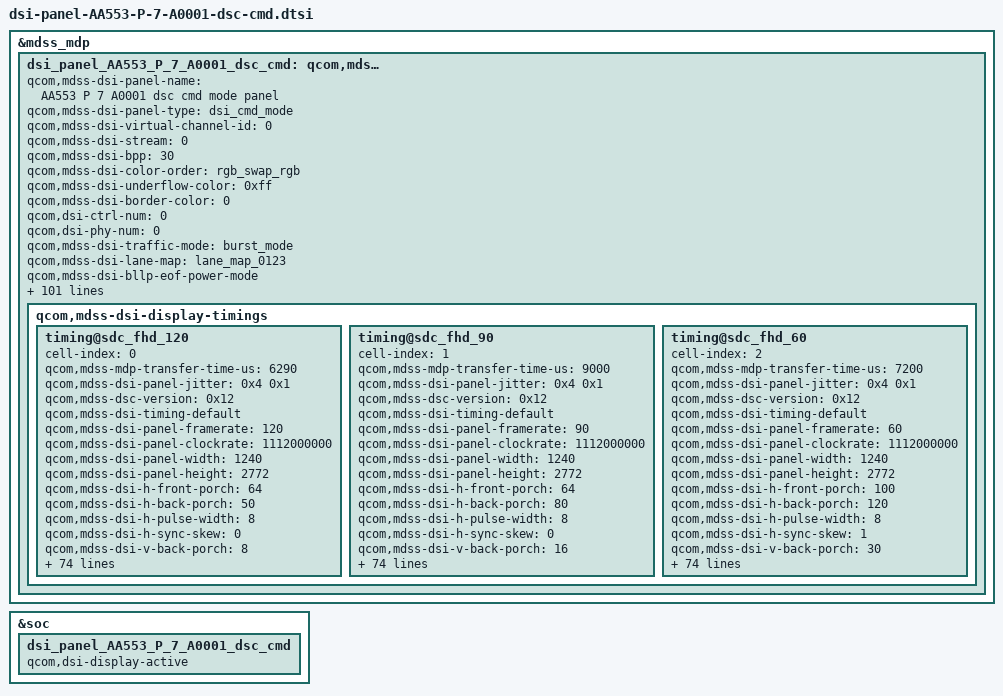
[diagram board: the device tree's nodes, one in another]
&mdss_mdp {
	dsi_panel_AA553_P_7_A0001_dsc_cmd: qcom,mdss_dsi_panel_AA553_P_7_A0001_dsc_cmd {
		qcom,mdss-dsi-panel-name = "AA553 P 7 A0001 dsc cmd mode panel";
		qcom,mdss-dsi-panel-type = "dsi_cmd_mode";
		qcom,mdss-dsi-virtual-channel-id = <0>;
		qcom,mdss-dsi-stream = <0>;
		qcom,mdss-dsi-bpp = <30>;
		qcom,mdss-dsi-color-order = "rgb_swap_rgb";
		qcom,mdss-dsi-underflow-color = <0xff>;
		qcom,mdss-dsi-border-color = <0>;
		qcom,dsi-ctrl-num = <0>;
		qcom,dsi-phy-num = <0>;
		qcom,mdss-dsi-traffic-mode = "burst_mode";
		qcom,mdss-dsi-lane-map = "lane_map_0123";
		qcom,mdss-dsi-bllp-eof-power-mode;
		qcom,mdss-dsi-bllp-power-mode;
		qcom,mdss-dsi-lane-0-state;
		qcom,mdss-dsi-lane-1-state;
		qcom,mdss-dsi-lane-2-state;
		qcom,mdss-dsi-lane-3-state;
		qcom,mdss-dsi-dma-trigger = "trigger_sw";
		qcom,mdss-dsi-dma-schedule-line = <1>;
		qcom,mdss-dsi-dma-schedule-window = <10>;
		qcom,mdss-dsi-mdp-trigger = "none";
		qcom,mdss-dsi-reset-sequence = <1 2>, <0 5>, <1 25>;
		qcom,mdss-dsi-te-pin-select = <1>;
		qcom,mdss-dsi-te-dcs-command = <1>;
		qcom,mdss-pan-physical-width-dimension = <70>;
		qcom,mdss-pan-physical-height-dimension = <156>;
		qcom,mdss-dsi-init-delay-us = <1000>;
		qcom,mdss-dsi-te-check-enable;
		qcom,mdss-dsi-te-using-te-pin;
		//qcom,mdss-dsi-lp11-init;
		qcom,mdss-dsi-wr-mem-start = <0x2c>;
		qcom,mdss-dsi-wr-mem-continue = <0x3c>;
		qcom,mdss-dsi-panel-jitter = <0x4 0x1>;
		qcom,mdss-dsc-scr-version = <0x1>;
		qcom,mdss-bl-high2bit;
		/* HDR Setting */
		qcom,mdss-dsi-panel-hdr-enabled;
		qcom,mdss-dsi-panel-hdr-color-primaries = <15635 16450 34000 16000 13250 34500 7500 3000>;
		qcom,mdss-dsi-panel-peak-brightness = <5400000>;
		qcom,mdss-dsi-panel-average-brightness = <2000000>;
		qcom,mdss-dsi-panel-blackness-level = <4000>;

		qcom,dynamic-mode-switch-enabled;
		qcom,dynamic-mode-switch-type = "dynamic-resolution-switch-immediate";
		qcom,mdss-dsi-display-timings {
			timing@sdc_fhd_120{
				cell-index = <0>;
				#include "dsi-panel-AA553-P-7-A0001-common.dtsi"
				qcom,mdss-mdp-transfer-time-us = <6290>;
				qcom,mdss-dsi-panel-jitter = <0x4 0x1>;
				qcom,mdss-dsc-version = <0x12>;
				qcom,mdss-dsi-timing-default;
				qcom,mdss-dsi-panel-framerate = <120>;
				qcom,mdss-dsi-panel-clockrate = <1112000000>;
				qcom,mdss-dsi-panel-width = <1240>;
				qcom,mdss-dsi-panel-height = <2772>;

				qcom,mdss-dsi-h-front-porch = <64>;
				qcom,mdss-dsi-h-back-porch = <50>;
				qcom,mdss-dsi-h-pulse-width = <8>;
				qcom,mdss-dsi-h-sync-skew = <0>;
				qcom,mdss-dsi-v-back-porch = <8>;
				qcom,mdss-dsi-v-front-porch = <2>;
				qcom,mdss-dsi-v-pulse-width = <2>;
				qcom,mdss-dsi-h-sync-pulse = <0>;

				qcom,mdss-dsi-h-left-border = <0>;
				qcom,mdss-dsi-h-right-border = <0>;
				qcom,mdss-dsi-v-top-border = <0>;
				qcom,mdss-dsi-v-bottom-border = <0>;

				oplus,ofp-need-to-sync-data-in-aod-unlocking;
				oplus,ofp-aod-off-insert-black-frame = <1>;
				oplus,ofp-aod-off-black-frame-total-time = <42>;
				oplus,ofp-uiready-delay-frames = <1>;

				qcom,mdss-dsi-timing-switch-command = [
					/* Frequence Transition 120hz*/
					15 00 00 60 00 00 02 2F 01
					/*LHBM Em duty */
					39 00 00 60 00 00 06 F0 55 AA 52 08 00
					39 00 00 60 00 00 02 6F 31
					39 00 00 60 00 00 02 DF 20
					39 00 00 60 00 00 02 6F 38
					39 00 00 20 00 00 03 DF 0A EC
				];
				qcom,mdss-dsi-on-command = [
					/* DVDD Strong */
					39 00 00 40 00 00 06 F0 55 AA 52 08 01
					15 00 00 40 00 00 02 6F 05
					39 00 00 00 00 00 05 C5 15 15 15 DD
					39 00 00 40 00 00 05 FF AA 55 A5 81
					15 00 00 40 00 00 02 6F 19
					15 00 00 40 00 00 02 FB 00
					15 00 00 40 00 00 02 6F 05
					15 00 00 40 00 00 02 FE 3C
					39 00 00 40 00 00 05 FF AA 55 A5 80
					15 00 00 40 00 00 02 6F 1A
					15 00 00 40 00 00 02 F4 55
					39 00 00 40 00 00 05 FF AA 55 A5 83
					15 00 00 40 00 00 02 6F 12
					15 00 00 40 00 00 02 FE 41
					15 00 00 40 00 00 02 5F 00
					15 00 00 40 00 00 02 26 00
					15 00 00 40 00 00 02 26 00
					15 00 00 40 00 00 02 17 10
					39 00 00 40 00 00 05 2A 00 00 04 D7
					39 00 00 40 00 00 05 2B 00 00 0A D3
					15 00 00 40 00 00 02 2F 01 /* Fre 120hz:0x01 90hz:0x02 60hz:0x03*/
					15 00 00 40 00 00 02 35 00
					39 00 00 40 00 00 03 44 00 00
					15 00 00 40 00 00 02 53 20
					39 00 00 00 00 00 03 90 03 03
					/* DSC Setting 10bit3.75 Version1.2 */
					39 00 00 40 00 00 13 91 AB A8 00 0C C2 00 02 37 01 33 00 08 08 BB 07 5F 10 F0
					39 00 00 40 00 00 05 FF AA 55 A5 81
					15 00 00 40 00 00 02 6F 24
					39 00 00 00 00 00 15 FB 00 03 04 55 77 77 77 99 9D 00 00 06 88 9A BB BC DE EF F0 11
					15 00 00 40 00 00 02 6F 0D
					15 00 00 40 00 00 02 FB 80
					39 00 00 40 00 00 05 FF AA 55 A5 81
					15 00 00 40 00 00 02 6F 0E
					15 00 00 40 00 00 02 F5 00
					39 00 00 40 00 00 05 FF AA 55 A5 80
					15 00 00 40 00 00 02 6F 0F
					15 00 00 40 00 00 02 FC 00
					15 00 00 40 00 00 02 6F 09
					39 00 00 40 00 00 03 FC FC F0
					39 00 00 40 00 00 05 FF AA 55 A5 80
					15 00 00 40 00 00 02 6F 0A
					39 00 00 40 00 00 04 F6 70 70 70
					15 00 00 40 00 00 02 6F 0E
					15 00 00 40 00 00 02 F6 60
					39 00 00 40 00 00 05 FF AA 55 A5 80
					15 00 00 40 00 00 02 6F 11
					39 00 00 40 00 00 03 F8 01 7C   /* OSC2=138.6M */
					15 00 00 40 00 00 02 6F 2D
					39 00 00 40 00 00 03 F8 00 FC
					15 00 00 40 00 00 02 6F 01
					15 00 00 40 00 00 02 1F 06
					39 00 00 40 00 00 05 FF AA 55 A5 81
					15 00 00 40 00 00 02 6F 1E
					15 00 00 40 00 00 02 FB 0F
					39 00 00 40 00 00 05 FF AA 55 A5 83
					15 00 00 40 00 00 02 6F 12
					15 00 00 40 00 00 02 FE 41
					39 00 00 40 00 00 05 FF AA 55 A5 80
					15 00 00 40 00 00 02 6F 19
					15 00 00 40 00 00 02 F2 00
					39 00 00 40 00 00 05 FF AA 55 A5 81
					15 00 00 40 00 00 02 6F 02
					15 00 00 40 00 00 02 F9 04
					15 00 00 00 00 00 02 5A 00
					/* OSC tracking 556MHz*/
					39 00 00 40 00 00 06 F0 55 AA 52 08 01
					39 00 00 00 00 00 2A C3 DD 06 22 11 FC 00 06 20 11
					                     FF 00 03 F2 12 05 FC 18 03 F2
					                     12 05 FC 18 03 F2 12 05 FC 18
					                     03 F2 12 05 FC 18 03 F2 12 05
					                     FC 18
					/*LHBM Icon Position */
					39 00 00 40 00 00 06 F0 55 AA 52 08 02
					39 00 00 40 00 00 0A 88 01 02 6C 09 D4 00 00 00 00
					/*LHBM Em duty */
					39 00 00 40 00 00 06 F0 55 AA 52 08 00
					39 00 00 40 00 00 02 6F 31
					39 00 00 40 00 00 02 DF 20
					39 00 00 40 00 00 02 6F 38
					39 00 00 00 00 00 03 DF 0A EC
					/* Increase the number of VFP rows */
					39 00 00 40 00 00 06 F0 55 AA 52 08 00
					39 00 00 40 00 00 16 BA 00 58 00 20 00 20 10 00 58
					                     00 20 03 D4 10 00 58 00 20 0B
					                     38 10
					39 00 00 40 00 00 06 F0 55 AA 52 08 00
					39 00 00 40 00 00 2F B4 00 00 00 C0 00 DC 00 DC 01
					                     10 01 10 01 A0 01 A0 02 B8 02
					                     B8 04 E8 04 E8 08 30 08 30 0A
					                     EC 0A EC 0A EC 0A EC 0A EC 0A
					                     EC 0A EC 0A EC 0A EC
					15 00 00 40 00 00 02 6F 2E
					39 00 00 40 00 00 2F B4 00 00 01 20 01 44 01 44 01
					                     90 01 90 02 44 02 44 03 B0 03
					                     B0 06 8C 06 8C 0A D0 0A D0 0E
					                     94 0E 94 0E 94 0E 94 0E 94 0E
					                     94 0E 94 0E 94 0E 94
					15 00 00 40 00 00 02 6F 5C
					39 00 00 00 00 00 2F B4 00 00 01 80 01 B8 01 B8 02
					                     28 02 28 03 40 03 40 05 70 05
					                     70 09 D4 09 D4 10 64 10 64 15
					                     E0 15 E0 15 E0 15 E0 15 E0 15
					                     E0 15 E0 15 E0 15 E0
					/*Sleep out*/
					05 00 00 00 78 00 01 11
					/*display on*/
					05 00 00 00 00 00 01 29
				];
				qcom,mdss-dsi-default-switch-page-command = [
					/*switch default page*/
					39 00 00 00 00 00 06 F0 55 AA 52 08 00
				];
				qcom,mdss-dsi-off-command=[
					39 00 00 00 46 00 06 F0 55 AA 52 08 00
					05 00 00 00 0A 00 01 28
					05 00 00 00 78 00 01 10
				];
				qcom,mdss-dsi-lp1-command = [
					/* AOD FD Discharge */
					39 00 00 40 00 00 06 F0 55 AA 52 08 00
					15 00 00 40 00 00 02 6F 0C
					39 00 00 40 00 00 03 B5 50 49
					/* AOD Mode ON */
					39 00 00 40 00 00 06 F0 55 AA 52 08 01
					15 00 00 40 00 00 02 6F 01
					15 00 00 40 00 00 02 D2 00
					05 00 00 40 00 00 01 39
					15 00 00 40 00 00 02 65 01
					/* AOD LV Switch */
					15 00 00 40 00 00 02 6F 04
					39 00 00 00 46 00 03 51 02 FF
				];
				qcom,mdss-dsi-nolp-command = [
					/* AOD FD Discharge */
					39 00 00 40 00 00 06 F0 55 AA 52 08 00
					15 00 00 40 00 00 02 6F 0C
					39 00 00 40 00 00 03 B5 4F 49
					/* AOD Mode OFF */
					39 00 00 40 00 00 06 F0 55 AA 52 08 01
					15 00 00 40 00 00 02 6F 01
					15 00 00 40 00 00 02 D2 00
					15 00 00 40 00 00 02 65 00
					05 00 00 00 00 00 01 38
				];
				qcom,mdss-dsi-hbm-off-command = [
					39 00 00 00 09 00 03 51 0D BB
					39 00 00 40 00 00 06 F0 55 AA 52 08 00
					39 00 00 40 00 00 02 6F 01
					39 00 00 00 00 00 02 B5 02
				];
				qcom,mdss-dsi-hbm-on-command = [
					39 00 00 00 00 00 03 51 0F 00
				];
				qcom,mdss-dsi-lhbm-update-vdc-command = [
					39 00 00 40 00 00 06 F0 55 AA 52 08 00
					39 00 00 40 00 00 02 DF 41
					39 00 00 40 00 00 02 6F 4C
					39 00 00 40 00 00 03 DF 21 48
					39 00 00 40 00 00 06 F0 55 AA 52 08 08
					39 00 00 40 00 00 02 6F 4A
					39 00 00 40 00 00 03 B8 08 00
					39 00 00 40 00 00 02 6F 4E
					39 00 00 00 00 00 03 B8 08 00
				];
				qcom,mdss-dsi-lhbm-dbv-alpha-command = [
					39 00 00 40 00 00 02 6F 01
					39 00 00 00 00 00 03 87 0F FF
				];
				qcom,mdss-dsi-lhbm-pressed-icon-on-command = [
					39 00 00 00 00 00 02 87 25
				];
				qcom,mdss-dsi-lhbm-pressed-icon-off-command = [
					39 00 00 00 00 00 02 87 20
				];
				qcom,mdss-dsi-aod-high-mode-command = [
					/* AOD 50nit */
					15 00 00 00 00 00 02 6F 04
					39 00 00 00 00 00 03 51 02 FF
				];
				qcom,mdss-dsi-aod-low-mode-command = [
					/* AOD 10nit */
					15 00 00 00 00 00 02 6F 04
					39 00 00 00 00 00 03 51 01 FF
				];
				qcom,mdss-dsi-timing-switch-command-state = "dsi_hs_mode";
				qcom,mdss-dsi-on-command-state = "dsi_lp_mode";
				qcom,mdss-dsi-off-command-state = "dsi_hs_mode";
				qcom,mdss-dsi-lp1-command-state = "dsi_lp_mode";
				qcom,mdss-dsi-nolp-command-state = "dsi_lp_mode";
				qcom,mdss-dsi-hbm-on-command-state = "dsi_lp_mode";
				qcom,mdss-dsi-hbm-off-command-state = "dsi_lp_mode";
				qcom,mdss-dsi-default-switch-page-command-state = "dsi_lp_mode";
				qcom,mdss-dsi-lhbm-pressed-icon-on-command-state = "dsi_hs_mode";
				qcom,mdss-dsi-lhbm-pressed-icon-off-command-state = "dsi_hs_mode";
				qcom,mdss-dsi-lhbm-update-vdc-command-state = "dsi_hs_mode";
				qcom,mdss-dsi-lhbm-dbv-alpha-command-state = "dsi_hs_mode";
				qcom,lm-split = <620 620>;
				qcom,compression-mode = "dsc";
				qcom,mdss-dsc-encoders = <2>;
				qcom,mdss-dsc-slice-height = <12>;
				qcom,mdss-dsc-slice-width = <620>;
				qcom,mdss-dsc-slice-per-pkt = <2>;
				qcom,mdss-dsc-bit-per-component = <10>;
				qcom,mdss-dsc-bit-per-pixel = <8>;
				qcom,mdss-dsc-block-prediction-enable;
				qcom,mdss-dsi-panel-id1-command-state = "dsi_lp_mode";
			};
			timing@sdc_fhd_90{
				cell-index = <1>;
				#include "dsi-panel-AA553-P-7-A0001-common.dtsi"
				qcom,mdss-mdp-transfer-time-us = <9000>;
				qcom,mdss-dsi-panel-jitter = <0x4 0x1>;
				qcom,mdss-dsc-version = <0x12>;
				qcom,mdss-dsi-timing-default;
				qcom,mdss-dsi-panel-framerate = <90>;
				qcom,mdss-dsi-panel-clockrate = <1112000000>;
				qcom,mdss-dsi-panel-width = <1240>;
				qcom,mdss-dsi-panel-height = <2772>;

				qcom,mdss-dsi-h-front-porch = <64>;
				qcom,mdss-dsi-h-back-porch = <80>;
				qcom,mdss-dsi-h-pulse-width = <8>;
				qcom,mdss-dsi-h-sync-skew = <0>;
				qcom,mdss-dsi-v-back-porch = <16>;
				qcom,mdss-dsi-v-front-porch = <10>;
				qcom,mdss-dsi-v-pulse-width = <2>;
				qcom,mdss-dsi-h-sync-pulse = <0>;

				qcom,mdss-dsi-h-left-border = <0>;
				qcom,mdss-dsi-h-right-border = <0>;
				qcom,mdss-dsi-v-top-border = <0>;
				qcom,mdss-dsi-v-bottom-border = <0>;

				oplus,ofp-need-to-sync-data-in-aod-unlocking;
				oplus,ofp-aod-off-insert-black-frame = <1>;
				oplus,ofp-aod-off-black-frame-total-time = <45>;
				oplus,ofp-uiready-delay-frames = <1>;

				qcom,mdss-dsi-timing-switch-command = [
					/* Frequence Transition 90hz*/
					15 00 00 60 00 00 02 2F 02
					/* Em duty */
					39 00 00 60 00 00 06 F0 55 AA 52 08 00
					39 00 00 60 00 00 02 6F 31
					39 00 00 60 00 00 02 DF 21
					39 00 00 60 00 00 02 6F 38
					39 00 00 20 00 00 03 DF 0E 94
				];
				qcom,mdss-dsi-on-command = [
					/* DVDD Strong */
					39 00 00 40 00 00 06 F0 55 AA 52 08 01
					15 00 00 40 00 00 02 6F 05
					39 00 00 00 00 00 05 C5 15 15 15 DD
					39 00 00 40 00 00 05 FF AA 55 A5 81
					15 00 00 40 00 00 02 6F 19
					15 00 00 40 00 00 02 FB 00
					15 00 00 40 00 00 02 6F 05
					15 00 00 40 00 00 02 FE 3C
					39 00 00 40 00 00 05 FF AA 55 A5 80
					15 00 00 40 00 00 02 6F 1A
					15 00 00 40 00 00 02 F4 55
					39 00 00 40 00 00 05 FF AA 55 A5 83
					15 00 00 40 00 00 02 6F 12
					15 00 00 40 00 00 02 FE 41
					15 00 00 40 00 00 02 5F 00
					15 00 00 40 00 00 02 26 00
					15 00 00 40 00 00 02 26 00
					15 00 00 40 00 00 02 17 10
					39 00 00 40 00 00 05 2A 00 00 04 D7
					39 00 00 40 00 00 05 2B 00 00 0A D3
					15 00 00 40 00 00 02 2F 02 /* Fre 120hz:0x01 90hz:0x02 60hz:0x03 */
					15 00 00 40 00 00 02 35 00
					39 00 00 40 00 00 03 44 00 00
					15 00 00 40 00 00 02 53 20
					39 00 00 00 00 00 03 90 03 03
					/* DSC Setting 10bit3.75 Version1.2 */
					39 00 00 40 00 00 13 91 AB A8 00 0C C2 00 02 37 01 33 00 08 08 BB 07 5F 10 F0
					39 00 00 40 00 00 05 FF AA 55 A5 81
					15 00 00 40 00 00 02 6F 24
					39 00 00 00 00 00 15 FB 00 03 04 55 77 77 77 99 9D 00 00 06 88 9A BB BC DE EF F0 11
					15 00 00 40 00 00 02 6F 0D
					15 00 00 40 00 00 02 FB 80
					39 00 00 40 00 00 05 FF AA 55 A5 81
					15 00 00 40 00 00 02 6F 0E
					15 00 00 40 00 00 02 F5 00
					39 00 00 40 00 00 05 FF AA 55 A5 80
					15 00 00 40 00 00 02 6F 0F
					15 00 00 40 00 00 02 FC 00
					15 00 00 40 00 00 02 6F 09
					39 00 00 40 00 00 03 FC FC F0
					39 00 00 40 00 00 05 FF AA 55 A5 80
					15 00 00 40 00 00 02 6F 0A
					39 00 00 40 00 00 04 F6 70 70 70
					15 00 00 40 00 00 02 6F 0E
					15 00 00 40 00 00 02 F6 60
					39 00 00 40 00 00 05 FF AA 55 A5 80
					15 00 00 40 00 00 02 6F 11
					39 00 00 40 00 00 03 F8 01 7C   /* OSC2=138.6M */
					15 00 00 40 00 00 02 6F 2D
					39 00 00 40 00 00 03 F8 00 FC
					15 00 00 40 00 00 02 6F 01
					15 00 00 40 00 00 02 1F 06
					39 00 00 40 00 00 05 FF AA 55 A5 81
					15 00 00 40 00 00 02 6F 1E
					15 00 00 40 00 00 02 FB 0F
					39 00 00 40 00 00 05 FF AA 55 A5 83
					15 00 00 40 00 00 02 6F 12
					15 00 00 40 00 00 02 FE 41
					39 00 00 40 00 00 05 FF AA 55 A5 80
					15 00 00 40 00 00 02 6F 19
					15 00 00 40 00 00 02 F2 00
					39 00 00 40 00 00 05 FF AA 55 A5 81
					15 00 00 40 00 00 02 6F 02
					15 00 00 40 00 00 02 F9 04
					15 00 00 00 00 00 02 5A 00
					/* OSC tracking 556MHz*/
					39 00 00 40 00 00 06 F0 55 AA 52 08 01
					39 00 00 00 00 00 2A C3 DD 06 22 11 FC 00 06 20 11
					                     FF 00 03 F2 12 05 FC 18 03 F2
					                     12 05 FC 18 03 F2 12 05 FC 18
					                     03 F2 12 05 FC 18 03 F2 12 05
					                     FC 18
					/* Icon Position */
					39 00 00 40 00 00 06 F0 55 AA 52 08 02
					39 00 00 40 00 00 0A 88 01 02 6C 09 D4 00 00 00 00
					/* Em duty */
					39 00 00 40 00 00 06 F0 55 AA 52 08 00
					39 00 00 40 00 00 02 6F 31
					39 00 00 40 00 00 02 DF 21
					39 00 00 40 00 00 02 6F 38
					39 00 00 00 00 00 03 DF 0E 94
					/* Increase the number of VFP rows */
					39 00 00 40 00 00 06 F0 55 AA 52 08 00
					39 00 00 40 00 00 16 BA 00 58 00 20 00 20 10 00 58
					                     00 20 03 D4 10 00 58 00 20 0B
					                     38 10
					39 00 00 40 00 00 06 F0 55 AA 52 08 00
					39 00 00 40 00 00 2F B4 00 00 00 C0 00 DC 00 DC 01
					                     10 01 10 01 A0 01 A0 02 B8 02
					                     B8 04 E8 04 E8 08 30 08 30 0A
					                     EC 0A EC 0A EC 0A EC 0A EC 0A
					                     EC 0A EC 0A EC 0A EC
					15 00 00 40 00 00 02 6F 2E
					39 00 00 40 00 00 2F B4 00 00 01 20 01 44 01 44 01
					                     90 01 90 02 44 02 44 03 B0 03
					                     B0 06 8C 06 8C 0A D0 0A D0 0E
					                     94 0E 94 0E 94 0E 94 0E 94 0E
					                     94 0E 94 0E 94 0E 94
					15 00 00 40 00 00 02 6F 5C
					39 00 00 00 00 00 2F B4 00 00 01 80 01 B8 01 B8 02
					                     28 02 28 03 40 03 40 05 70 05
					                     70 09 D4 09 D4 10 64 10 64 15
					                     E0 15 E0 15 E0 15 E0 15 E0 15
					                     E0 15 E0 15 E0 15 E0
					/*Sleep out*/
					05 00 00 00 78 00 01 11
					/*display on*/
					05 00 00 00 00 00 01 29
				];
				qcom,mdss-dsi-default-switch-page-command = [
					/*switch default page*/
					39 00 00 00 00 00 06 F0 55 AA 52 08 00
				];
				qcom,mdss-dsi-off-command=[
					39 00 00 00 46 00 06 F0 55 AA 52 08 00
					05 00 00 00 0A 00 01 28
					05 00 00 00 78 00 01 10
				];
				qcom,mdss-dsi-lp1-command = [
					/* AOD FD Discharge */
					39 00 00 40 00 00 06 F0 55 AA 52 08 00
					15 00 00 40 00 00 02 6F 0C
					39 00 00 40 00 00 03 B5 50 49
					/* AOD Mode ON */
					39 00 00 40 00 00 06 F0 55 AA 52 08 01
					15 00 00 40 00 00 02 6F 01
					15 00 00 40 00 00 02 D2 00
					05 00 00 40 00 00 01 39
					15 00 00 40 00 00 02 65 01
					/* AOD LV Switch */
					15 00 00 40 00 00 02 6F 04
					39 00 00 00 46 00 03 51 02 FF
				];
				qcom,mdss-dsi-nolp-command = [
					/* AOD FD Discharge */
					39 00 00 40 00 00 06 F0 55 AA 52 08 00
					15 00 00 40 00 00 02 6F 0C
					39 00 00 40 00 00 03 B5 4F 49
					/* AOD Mode OFF */
					39 00 00 40 00 00 06 F0 55 AA 52 08 01
					15 00 00 40 00 00 02 6F 01
					15 00 00 40 00 00 02 D2 00
					15 00 00 40 00 00 02 65 00
					05 00 00 00 00 00 01 38
				];
				qcom,mdss-dsi-hbm-off-command = [
					39 00 00 00 0C 00 03 51 0D BB
					39 00 00 40 00 00 06 F0 55 AA 52 08 00
					39 00 00 40 00 00 02 6F 01
					39 00 00 00 00 00 02 B5 02
				];
				qcom,mdss-dsi-hbm-on-command = [
					39 00 00 00 00 00 03 51 0F 00
				];
				qcom,mdss-dsi-lhbm-update-vdc-command = [
					39 00 00 40 00 00 06 F0 55 AA 52 08 00
					39 00 00 40 00 00 02 DF 41
					39 00 00 40 00 00 02 6F 4C
					39 00 00 40 00 00 03 DF 21 48
					39 00 00 40 00 00 06 F0 55 AA 52 08 08
					39 00 00 40 00 00 02 6F 4A
					39 00 00 40 00 00 03 B8 08 00
					39 00 00 40 00 00 02 6F 4E
					39 00 00 00 00 00 03 B8 08 00
				];
				qcom,mdss-dsi-lhbm-dbv-alpha-command = [
					39 00 00 40 00 00 02 6F 01
					39 00 00 00 00 00 03 87 0F FF
				];
				qcom,mdss-dsi-lhbm-pressed-icon-on-command = [
					39 00 00 00 00 00 02 87 25
				];
				qcom,mdss-dsi-lhbm-pressed-icon-off-command = [
					39 00 00 00 00 00 02 87 20
				];
				qcom,mdss-dsi-aod-high-mode-command = [
					/* AOD 50nit */
					15 00 00 00 00 00 02 6F 04
					39 00 00 00 00 00 03 51 02 FF
				];
				qcom,mdss-dsi-aod-low-mode-command = [
					/* AOD 10nit */
					15 00 00 00 00 00 02 6F 04
					39 00 00 00 00 00 03 51 01 FF
				];

				qcom,mdss-dsi-timing-switch-command-state = "dsi_hs_mode";
				qcom,mdss-dsi-on-command-state = "dsi_lp_mode";
				qcom,mdss-dsi-off-command-state = "dsi_hs_mode";
				qcom,mdss-dsi-lp1-command-state = "dsi_lp_mode";
				qcom,mdss-dsi-nolp-command-state = "dsi_lp_mode";
				qcom,mdss-dsi-hbm-on-command-state = "dsi_lp_mode";
				qcom,mdss-dsi-hbm-off-command-state = "dsi_lp_mode";
				qcom,mdss-dsi-lhbm-pressed-icon-on-command-state = "dsi_hs_mode";
				qcom,mdss-dsi-lhbm-pressed-icon-off-command-state = "dsi_hs_mode";
				qcom,mdss-dsi-lhbm-update-vdc-command-state = "dsi_hs_mode";
				qcom,mdss-dsi-lhbm-dbv-alpha-command-state = "dsi_hs_mode";
				qcom,mdss-dsi-default-switch-page-command-state = "dsi_lp_mode";

				qcom,lm-split = <620 620>;
				qcom,compression-mode = "dsc";
				qcom,mdss-dsc-encoders = <2>;
				qcom,mdss-dsc-slice-height = <12>;
				qcom,mdss-dsc-slice-width = <620>;
				qcom,mdss-dsc-slice-per-pkt = <2>;
				qcom,mdss-dsc-bit-per-component = <10>;
				qcom,mdss-dsc-bit-per-pixel = <8>;
				qcom,mdss-dsc-block-prediction-enable;
				qcom,mdss-dsi-panel-id1-command-state = "dsi_lp_mode";
			};
			timing@sdc_fhd_60{
				cell-index = <2>;
				#include "dsi-panel-AA553-P-7-A0001-common.dtsi"
				qcom,mdss-mdp-transfer-time-us = <7200>;
				qcom,mdss-dsi-panel-jitter = <0x4 0x1>;
				qcom,mdss-dsc-version = <0x12>;
				qcom,mdss-dsi-timing-default;
				qcom,mdss-dsi-panel-framerate = <60>;
				qcom,mdss-dsi-panel-clockrate = <1112000000>;
				qcom,mdss-dsi-panel-width = <1240>;
				qcom,mdss-dsi-panel-height = <2772>;

				qcom,mdss-dsi-h-front-porch = <100>;
				qcom,mdss-dsi-h-back-porch = <120>;
				qcom,mdss-dsi-h-pulse-width = <8>;
				qcom,mdss-dsi-h-sync-skew = <1>;
				qcom,mdss-dsi-v-back-porch = <30>;
				qcom,mdss-dsi-v-front-porch = <20>;
				qcom,mdss-dsi-v-pulse-width = <2>;
				qcom,mdss-dsi-h-sync-pulse = <0>;

				qcom,mdss-dsi-h-left-border = <0>;
				qcom,mdss-dsi-h-right-border = <0>;
				qcom,mdss-dsi-v-top-border = <0>;
				qcom,mdss-dsi-v-bottom-border = <0>;

				oplus,ofp-need-to-sync-data-in-aod-unlocking;
				oplus,ofp-aod-off-insert-black-frame = <2>;
				oplus,ofp-aod-off-black-frame-total-time = <59>;
				oplus,ofp-uiready-delay-frames = <1>;

				qcom,mdss-dsi-timing-switch-command = [
					/* Frequence Transition 60hz*/
					15 00 00 60 00 00 02 2F 03
					/* Em duty */
					39 00 00 60 00 00 06 F0 55 AA 52 08 00
					39 00 00 60 00 00 02 6F 31
					39 00 00 60 00 00 02 DF 22
					39 00 00 60 00 00 02 6F 38
					39 00 00 20 00 00 03 DF 15 E0
				];
				qcom,mdss-dsi-on-command = [
					/* DVDD Strong */
					39 00 00 40 00 00 06 F0 55 AA 52 08 01
					15 00 00 40 00 00 02 6F 05
					39 00 00 00 00 00 05 C5 15 15 15 DD
					39 00 00 40 00 00 05 FF AA 55 A5 81
					15 00 00 40 00 00 02 6F 19
					15 00 00 40 00 00 02 FB 00
					15 00 00 40 00 00 02 6F 05
					15 00 00 40 00 00 02 FE 3C
					39 00 00 40 00 00 05 FF AA 55 A5 80
					15 00 00 40 00 00 02 6F 1A
					15 00 00 40 00 00 02 F4 55
					39 00 00 40 00 00 05 FF AA 55 A5 83
					15 00 00 40 00 00 02 6F 12
					15 00 00 40 00 00 02 FE 41
					15 00 00 40 00 00 02 5F 00
					15 00 00 40 00 00 02 26 00
					15 00 00 40 00 00 02 26 00
					15 00 00 40 00 00 02 17 10
					39 00 00 40 00 00 05 2A 00 00 04 D7
					39 00 00 40 00 00 05 2B 00 00 0A D3
					15 00 00 40 00 00 02 2F 03 /* Fre 120hz:0x01 90hz:0x02 60hz:0x03 */
					15 00 00 40 00 00 02 35 00
					39 00 00 40 00 00 03 44 00 00
					15 00 00 40 00 00 02 53 20
					39 00 00 00 00 00 03 90 03 03
					/* DSC Setting 10bit3.75 Version1.2 */
					39 00 00 40 00 00 13 91 AB A8 00 0C C2 00 02 37 01 33 00 08 08 BB 07 5F 10 F0
					39 00 00 40 00 00 05 FF AA 55 A5 81
					15 00 00 40 00 00 02 6F 24
					39 00 00 00 00 00 15 FB 00 03 04 55 77 77 77 99 9D 00 00 06 88 9A BB BC DE EF F0 11
					15 00 00 40 00 00 02 6F 0D
					15 00 00 40 00 00 02 FB 80
					39 00 00 40 00 00 05 FF AA 55 A5 81
					15 00 00 40 00 00 02 6F 0E
					15 00 00 40 00 00 02 F5 00
					39 00 00 40 00 00 05 FF AA 55 A5 80
					15 00 00 40 00 00 02 6F 0F
					15 00 00 40 00 00 02 FC 00
					15 00 00 40 00 00 02 6F 09
					39 00 00 40 00 00 03 FC FC F0
					39 00 00 40 00 00 05 FF AA 55 A5 80
					15 00 00 40 00 00 02 6F 0A
					39 00 00 40 00 00 04 F6 70 70 70
					15 00 00 40 00 00 02 6F 0E
					15 00 00 40 00 00 02 F6 60
					39 00 00 40 00 00 05 FF AA 55 A5 80
					15 00 00 40 00 00 02 6F 11
					39 00 00 40 00 00 03 F8 01 7C   /* OSC2=138.6M */
					15 00 00 40 00 00 02 6F 2D
					39 00 00 40 00 00 03 F8 00 FC
					15 00 00 40 00 00 02 6F 01
					15 00 00 40 00 00 02 1F 06
					39 00 00 40 00 00 05 FF AA 55 A5 81
					15 00 00 40 00 00 02 6F 1E
					15 00 00 40 00 00 02 FB 0F
					39 00 00 40 00 00 05 FF AA 55 A5 83
					15 00 00 40 00 00 02 6F 12
					15 00 00 40 00 00 02 FE 41
					39 00 00 40 00 00 05 FF AA 55 A5 80
					15 00 00 40 00 00 02 6F 19
					15 00 00 40 00 00 02 F2 00
					39 00 00 40 00 00 05 FF AA 55 A5 81
					15 00 00 40 00 00 02 6F 02
					15 00 00 40 00 00 02 F9 04
					15 00 00 00 00 00 02 5A 00
					/* OSC tracking 556MHz*/
					39 00 00 40 00 00 06 F0 55 AA 52 08 01
					39 00 00 00 00 00 2A C3 DD 06 22 11 FC 00 06 20 11
					                     FF 00 03 F2 12 05 FC 18 03 F2
					                     12 05 FC 18 03 F2 12 05 FC 18
					                     03 F2 12 05 FC 18 03 F2 12 05
					                     FC 18
					/* Icon Position */
					39 00 00 40 00 00 06 F0 55 AA 52 08 02
					39 00 00 40 00 00 0A 88 01 02 6C 09 D4 00 00 00 00
					/* Em duty */
					39 00 00 40 00 00 06 F0 55 AA 52 08 00
					39 00 00 40 00 00 02 6F 31
					39 00 00 40 00 00 02 DF 22
					39 00 00 40 00 00 02 6F 38
					39 00 00 00 00 00 03 DF 15 E0
					/* Increase the number of VFP rows */
					39 00 00 40 00 00 06 F0 55 AA 52 08 00
					39 00 00 40 00 00 16 BA 00 58 00 20 00 20 10 00 58
					                     00 20 03 D4 10 00 58 00 20 0B
					                     38 10
					39 00 00 40 00 00 06 F0 55 AA 52 08 00
					39 00 00 40 00 00 2F B4 00 00 00 C0 00 DC 00 DC 01
					                     10 01 10 01 A0 01 A0 02 B8 02
					                     B8 04 E8 04 E8 08 30 08 30 0A
					                     EC 0A EC 0A EC 0A EC 0A EC 0A
					                     EC 0A EC 0A EC 0A EC
					15 00 00 40 00 00 02 6F 2E
					39 00 00 40 00 00 2F B4 00 00 01 20 01 44 01 44 01
					                     90 01 90 02 44 02 44 03 B0 03
					                     B0 06 8C 06 8C 0A D0 0A D0 0E
					                     94 0E 94 0E 94 0E 94 0E 94 0E
					                     94 0E 94 0E 94 0E 94
					15 00 00 40 00 00 02 6F 5C
					39 00 00 00 00 00 2F B4 00 00 01 80 01 B8 01 B8 02
					                     28 02 28 03 40 03 40 05 70 05
					                     70 09 D4 09 D4 10 64 10 64 15
					                     E0 15 E0 15 E0 15 E0 15 E0 15
					                     E0 15 E0 15 E0 15 E0
					/*Sleep out*/
					05 00 00 00 78 00 01 11
					/*display on*/
					05 00 00 00 00 00 01 29
				];
				qcom,mdss-dsi-default-switch-page-command = [
					/*switch default page*/
					39 00 00 00 00 00 06 F0 55 AA 52 08 00
				];
				qcom,mdss-dsi-off-command=[
					39 00 00 00 46 00 06 F0 55 AA 52 08 00
					05 00 00 00 0A 00 01 28
					05 00 00 00 78 00 01 10
				];
				qcom,mdss-dsi-lp1-command = [
					/* AOD FD Discharge */
					39 00 00 40 00 00 06 F0 55 AA 52 08 00
					15 00 00 40 00 00 02 6F 0C
					39 00 00 40 00 00 03 B5 50 49
					/* AOD Mode ON */
					39 00 00 40 00 00 06 F0 55 AA 52 08 01
					15 00 00 40 00 00 02 6F 01
					15 00 00 40 00 00 02 D2 00
					05 00 00 40 00 00 01 39
					15 00 00 40 00 00 02 65 01
					/* AOD LV Switch */
					15 00 00 40 00 00 02 6F 04
					39 00 00 00 46 00 03 51 02 FF
				];
				qcom,mdss-dsi-nolp-command = [
					/* AOD FD Discharge */
					39 00 00 40 00 00 06 F0 55 AA 52 08 00
					15 00 00 40 00 00 02 6F 0C
					39 00 00 40 00 00 03 B5 4F 49
					/* AOD Mode OFF */
					39 00 00 40 00 00 06 F0 55 AA 52 08 01
					15 00 00 40 00 00 02 6F 01
					15 00 00 40 00 00 02 D2 00
					15 00 00 40 00 00 02 65 00
					05 00 00 00 00 00 01 38
				];
				qcom,mdss-dsi-hbm-off-command = [
					39 00 00 00 00 00 03 51 0D BB
				];
				qcom,mdss-dsi-hbm-on-command = [
					39 00 00 00 00 00 03 51 0F 00
				];
				qcom,mdss-dsi-lhbm-update-vdc-command = [
					39 00 00 40 00 00 06 F0 55 AA 52 08 00
					39 00 00 40 00 00 02 DF 41
					39 00 00 40 00 00 02 6F 4C
					39 00 00 40 00 00 03 DF 21 48
					39 00 00 40 00 00 06 F0 55 AA 52 08 08
					39 00 00 40 00 00 02 6F 4A
					39 00 00 40 00 00 03 B8 08 00
					39 00 00 40 00 00 02 6F 4E
					39 00 00 00 00 00 03 B8 08 00
				];
				qcom,mdss-dsi-lhbm-dbv-alpha-command = [
					39 00 00 40 00 00 02 6F 01
					39 00 00 00 00 00 03 87 0F FF
				];
				qcom,mdss-dsi-lhbm-pressed-icon-on-command = [
					39 00 00 00 00 00 02 87 25
				];
				qcom,mdss-dsi-lhbm-pressed-icon-off-command = [
					39 00 00 00 00 00 02 87 20
				];
				qcom,mdss-dsi-aod-high-mode-command = [
					/* AOD 50nit */
					15 00 00 00 00 00 02 6F 04
					39 00 00 00 00 00 03 51 02 FF
				];
				qcom,mdss-dsi-aod-low-mode-command = [
					/* AOD 10nit */
					15 00 00 00 00 00 02 6F 04
					39 00 00 00 00 00 03 51 01 FF
				];

				qcom,mdss-dsi-timing-switch-command-state = "dsi_hs_mode";
				qcom,mdss-dsi-on-command-state = "dsi_lp_mode";
				qcom,mdss-dsi-off-command-state = "dsi_hs_mode";
				qcom,mdss-dsi-lp1-command-state = "dsi_lp_mode";
				qcom,mdss-dsi-nolp-command-state = "dsi_lp_mode";
				qcom,mdss-dsi-hbm-on-command-state = "dsi_lp_mode";
				qcom,mdss-dsi-hbm-off-command-state = "dsi_lp_mode";
				qcom,mdss-dsi-lhbm-pressed-icon-on-command-state = "dsi_hs_mode";
				qcom,mdss-dsi-lhbm-pressed-icon-off-command-state = "dsi_hs_mode";
				qcom,mdss-dsi-lhbm-update-vdc-command-state = "dsi_hs_mode";
				qcom,mdss-dsi-lhbm-dbv-alpha-command-state = "dsi_hs_mode";
				qcom,mdss-dsi-default-switch-page-command-state = "dsi_lp_mode";

				qcom,lm-split = <620 620>;
				qcom,compression-mode = "dsc";
				qcom,mdss-dsc-encoders = <2>;
				qcom,mdss-dsc-slice-height = <12>;
				qcom,mdss-dsc-slice-width = <620>;
				qcom,mdss-dsc-slice-per-pkt = <2>;
				qcom,mdss-dsc-bit-per-component = <10>;
				qcom,mdss-dsc-bit-per-pixel = <8>;
				qcom,mdss-dsc-block-prediction-enable;
				qcom,mdss-dsi-panel-id1-command-state = "dsi_lp_mode";
			};
		};
	};
};

&soc {
	dsi_panel_AA553_P_7_A0001_dsc_cmd {
		qcom,dsi-display-active;
	};
};

&dsi_panel_AA553_P_7_A0001_dsc_cmd {
	qcom,ulps-enabled;
	qcom,dsi-select-clocks = "pll_byte_clk0", "pll_dsi_clk0";

	qcom,mdss-dsi-display-timings {
		timing@sdc_fhd_120 { /* FHD+ 120hz 556Mhz 1112Mbps */
			qcom,mdss-dsi-panel-phy-timings = [00 24 0A 0A 1A 18 0A 0A 09 02 04 00 1E 0F];
			qcom,display-topology = <1 1 1>,<2 2 1>;
			qcom,default-topology-index = <1>;
		};
		timing@sdc_fhd_90 { /* FHD+ 90hz 556Mhz 1112Mbps */
			qcom,mdss-dsi-panel-phy-timings = [00 24 0A 0A 1A 18 0A 0A 09 02 04 00 1E 0F];
			qcom,display-topology = <1 1 1>,<2 2 1>;
			qcom,default-topology-index = <1>;
		};
		timing@sdc_fhd_60 { /* FHD+ 60hz 556Mhz 1112Mbps */
			qcom,mdss-dsi-panel-phy-timings = [00 24 0A 0A 1A 18 0A 0A 09 02 04 00 1E 0F];
			qcom,display-topology = <1 1 1>,<2 2 1>;
			qcom,default-topology-index = <1>;
		};
	};
};
&dsi_panel_AA553_P_7_A0001_dsc_cmd {
	qcom,panel_voltage_vddi_name = "vddio";
	qcom,panel_voltage_vddi = <0 1800000 1850000 1950000>;
	qcom,panel_voltage_vddr_name = "vddio";
	qcom,panel_voltage_vddr = <1 1800000 1850000 1950000>;
};

&dsi_panel_AA553_P_7_A0001_dsc_cmd {
	oplus,color_vivid_status;
	oplus,color_srgb_status;
	oplus,color_softiris_status;
	oplus,color_dual_brightness_status;
	oplus,color_2nit_status;
	oplus,color_oplus_calibrate_status;
	oplus,color_samsung_status;
	oplus,color_loading_status;
	oplus,color_nature_profession_status;
	oplus,mdss-dsi-panel-type = <2>;

	/* HARDWARE CONFIG */
	qcom,panel-supply-entries = <&oplus_dsi_panel_custom_pwr_supply>;
	qcom,mdss-dsi-panel-controller = <&mdss_dsi0>;
	qcom,platform-te-gpio = <&tlmm 77 0>;
	qcom,dynamic-te-gpio = <&tlmm 76 0>;
	qcom,platform-reset-gpio = <&tlmm 79 0>;
	qcom,platform-panel-vout-gpio = <&tlmm 116 0>;

	/* BRIGHTNESS CONFIG */
	qcom,mdss-dsi-bl-pmic-control-type = "bl_ctrl_dcs";
	qcom,bl-dsc-cmd-state = "dsi_hs_mode";
	qcom,bl-update-flag = "delay_until_first_frame";
	qcom,mdss-dsi-bl-inverted-dbv;
	qcom,mdss-dsi-bl-min-level = <1>;
	qcom,mdss-dsi-bl-max-level = <3999>;
	qcom,mdss-brightness-max-level = <3999>;
	oplus,dsi-bl-normal-max-level = <3238>;
	oplus,dsi-brightness-normal-max-level = <3238>;
	oplus,dsi-dc-backlight-threshold = <1960>;
	oplus,dsi-brightness-default-level = <1638>;
	oplus,dsi_demura2_offset_support;

	/* FACTORY CONFIG */
	oplus,mdss-dsi-vendor-name = "A0001";
	oplus,mdss-dsi-manufacture = "P_7";
	oplus,color_vivid_status;
	oplus,color_srgb_status;
	oplus,color_softiris_status;
	oplus,color_dual_brightness_status;

	/* serial num config */
	oplus,dsi-serial-number-enabled;
	oplus,dsi-serial-number-index= <0>;
	oplus,dsi-serial-number-reg= <0xA3>;
	oplus,dsi-serial-number-read-count= <7>;

	/* ESD CONFIG */
	qcom,esd-check-enabled;
	qcom,mdss-dsi-panel-status-check-mode = "reg_read";
	qcom,mdss-dsi-panel-status-command = [
		06 00 00 00 00 00 01 0A
		06 00 00 00 00 00 01 91
		06 00 00 00 00 00 01 03
		06 00 00 00 00 00 01 2B
	];
	qcom,mdss-dsi-panel-status-command-state = "dsi_lp_mode";
	qcom,mdss-dsi-panel-status-value = <0x9C 0xAB 0x00 0x00 0x00 0x0A 0xD3>;
	qcom,mdss-dsi-panel-status-read-length = <1 1 1 4>;
	oplus,mdss-dsi-panel-status-match-modes = <0x00000000>;

	/* OPLUS FEATURES CONFIG */
	/* adfr config */
	oplus,adfr-config = <0x0>;

	/* temp-compensation config */
	oplus,temp-compensation-config = <0x0>;

	/* ofp config */
	oplus,ofp-fp-type = <0x98>;
	oplus,ofp-longrui-aod-config = <0x02>;
	oplus,ofp-need-to-wait-data-before-aod-on;
	oplus,ofp-local-hbm-is-enabled;
	oplus,ofp-need-to-update-lhbm-vdc;
	oplus,ofp-lhbm-dbv-alpha-cmd-index = <1>;
	oplus,ofp-lhbm-dbv-alpha-register-offset = <1>;
	oplus,ofp-lhbm-dbv-alpha-value = <
		/* lhbm dbv alpha value from 0 to 522 */
		811 811 811 811 811 811 811 811 811 811 812 812 812 813 816 816 816 818 818 818 819 822 822 822 823 824 825 825 825 828
		828 830 830 831 832 833 834 835 836 838 837 838 841 840 841 842 844 844 844 845 846 845 848 848 848 849 850 851 851 852
		853 854 854 855 857 860 861 862 863 863 864 865 865 866 867 867 868 869 870 870 871 871 873 872 874 876 875 876 876 879
		878 879 881 880 884 885 885 887 888 888 889 888 891 891 893 893 895 895 895 897 897 898 898 900 900 901 901 901 903 904
		904 904 909 910 909 910 913 913 913 914 914 916 916 917 916 917 920 919 920 920 923 924 923 925 927 926 929 928 929 930
		930 935 935 935 936 935 938 939 938 939 940 942 941 943 944 944 945 945 947 948 948 949 950 951 950 952 954 952 956 960
		960 962 962 964 963 964 966 965 968 967 969 971 971 972 972 973 973 974 975 975 976 976 980 982 984 986 984 990 990 991 992
		994 998 1000 1000 1002 1002 1004 1006 1006 1012 1012 1014 1015 1015 1019 1019 1021 1023 1030 1030 1030 1032 1033 1034 1035
		1035 1037 1043 1044 1045 1047 1049 1050 1052 1053 1055 1061 1065 1065 1067 1067 1069 1071 1072 1073 1080 1081 1083 1086 1088
		1089 1090 1092 1092 1099 1101 1102 1106 1107 1108 1110 1112 1112 1122 1122 1124 1126 1128 1130 1131 1132 1138 1140 1141 1144
		1146 1148 1149 1150 1152 1158 1160 1161 1164 1165 1167 1168 1171 1173 1179 1182 1183 1186 1187 1189 1192 1193 1195 1201 1202
		1205 1206 1207 1209 1212 1215 1215 1223 1225 1227 1229 1229 1233 1234 1233 1238 1241 1242 1243 1243 1251 1254 1255 1254 1258
		1260 1263 1266 1265 1267 1273 1275 1275 1278 1278 1287 1288 1288 1291 1291 1296 1297 1299 1302 1302 1305 1308 1312 1311 1316
		1316 1323 1324 1323 1325 1327 1334 1334 1336 1336 1339 1347 1349 1350 1351 1352 1359 1360 1361 1362 1365 1373 1374 1376 1376
		1377 1384 1385 1387 1389 1389 1397 1396 1398 1400 1400 1410 1411 1413 1414 1415 1417 1423 1426 1426 1428 1430 1438 1438 1439
		1441 1443 1451 1451 1454 1454 1454 1463 1463 1466 1468 1469 1476 1479 1479 1481 1483 1490 1492 1492 1493 1496 1504 1505 1505
		1508 1509 1517 1518 1519 1519 1522 1524 1531 1532 1536 1537 1538 1544 1546 1547 1550 1550 1557 1559 1560 1563 1566 1572 1573
		1575 1576 1579 1587 1588 1590 1591 1591 1601 1601 1604 1605 1607 1614 1617 1617 1619 1622 1630 1631 1632 1633 1638 1638 1645
		1646 1649 1650 1652 1661 1662 1664 1665 1668 1675 1679 1679 1680 1683 1690 1693 1692 1692 1699 1698 1701 1708 1705 1709 1716
		1716 1715 1719 1726 1725 1728 1734 1735 1735 1742 1744 1743 1751 1753 1753 1761 1762 1762 1768 1770 1770 1778 1776 1779 1780
		1787 1788 1789 1797 1796 1797 1804 1806 1807 1814 1814 1814 1823 1823 1825 1830 1830 1833 1838 1840 1841 1842 1848 1849 1851
		1859 1859 1860 1869 1869 1870 1878 1880 1881 1886 1891 1891 1897 1899 1892 1894 1898 1904 1903 1910 1911 1913 1918 1919 1921
		1929 1930 1932 1938 1938 1942 1947 1950 1951 1958 1960 1961 1962 1968 1971 1971 1977 1980 1982 1988 1990 1991 1998 1997 2001
		2006 2009 2009 2017 2017 2018 2021 2026 2027 2029 2035 2037 2038 2048 2047 2049 2056 2057 2058 2065 2066 2068 2075 2076 2077
		2084 2085 2086 2088 2093 2094 2095 2103 2104 2105 2114 2114 2109 2112 2119 2116 2124 2125 2124 2132 2133 2138 2143 2144 2145
		2145 2150 2155 2156 2160 2162 2164 2169 2172 2172 2179 2181 2181 2189 2189 2191 2198 2199 2200 2200 2207 2210 2211 2217 2218
		2217 2227 2226 2227 2234 2238 2237 2244 2246 2248 2252 2252 2254 2263 2264 2264 2266 2273 2273 2275 2281 2281 2283 2288 2290
		2293 2298 2300 2299 2310 2310 2308 2318 2319 2318 2323 2321 2321 2327 2328 2333 2332 2337 2338 2346 2345 2350 2350 2356 2355
		2361 2361 2371 2370 2377 2376 2382 2384 2388 2388 2396 2398 2403 2403 2403 2410 2411 2416 2418 2425 2426 2431 2432 2437 2438
		2444 2446 2451 2451 2460 2459 2464 2464 2471 2474 2479 2479 2485 2485 2493 2493 2491 2499 2502 2505 2506 2512 2512 2517 2516
		2526 2525 2532 2533 2537 2539 2545 2544 2552 2550 2558 2558 2565 2565 2571 2571 2578 2576 2580 2587 2586 2592 2591 2598 2599
		2604 2605 2611 2612 2617 2618 2623 2624 2630 2631 2636 2637 2642 2641 2648 2647 2654 2654 2661 2662 2667 2667 2667 2672 2673
		2679 2680 2685 2685 2693 2691 2698 2697 2702 2704 2710 2710 2715 2716 2721 2723 2727 2726 2735 2733 2738 2737 2747 2748 2746
		2751 2753 2758 2757 2764 2759 2762 2763 2768 2770 2776 2774 2778 2782 2789 2786 2792 2795 2798 2796 2802 2807 2812 2810 2817
		2816 2817 2824 2823 2831 2830 2834 2834 2840 2840 2846 2847 2852 2852 2858 2856 2862 2864 2870 2869 2877 2873 2879 2879 2883
		2887 2891 2893 2894 2895 2898 2903 2902 2910 2911 2915 2917 2924 2921 2928 2927 2933 2934 2940 2942 2947 2947 2951 2953 2958
		2960 2966 2966 2970 2970 2977 2978 2978 2982 2984 2988 2988 2995 2996 3001 3002 3005 3009 3015 3014 3020 3021 3024 3025 3031
		3034 3035 3038 3043 3044 3048 3048 3051 3055 3056 3061 3064 3069 3067 3071 3071 3078 3081 3084 3086 3090 3090 3096 3095 3100
		3104 3109 3110 3114 3116 3117 3117 3123 3127 3133 3132 3133 3136 3139 3142 3141 3149 3150 3156 3156 3161 3161 3165 3164 3169
		3169 3173 3177 3180 3180 3185 3190 3189 3194 3197 3199 3201 3207 3206 3211 3219 3220 3225 3229 3231 3231 3236 3241 3239 3243
		3248 3246 3254 3257 3259 3263 3269 3270 3275 3278 3283 3283 3287 3290 3292 3296 3298 3296 3304 3307 3311 3313 3320 3323 3321
		3328 3331 3332 3337 3342 3341 3343 3349 3350 3353 3358 3357 3363 3368 3371 3372 3374 3382 3379 3386 3389 3389 3393 3398 3398
		3403 3408 3407 3411 3414 3420 3421 3421 3427 3427 3432 3437 3437 3439 3446 3450 3450 3457 3462 3462 3466 3471 3471 3473 3480
		3482 3486 3490 3489 3494 3496 3502 3506 3510 3515 3513 3520 3521 3522 3527 3533 3534 3539 3543 3543 3548 3554 3552 3558 3564
		3567 3568 3572 3576 3577 3584 3586 3585 3590 3597 3595 3602 3609 3612 3611 3616 3617 3620 3626 3631 3630 3633 3638 3640 3641
		3647 3644 3648 3652 3657 3656 3660 3667 3668 3671 3676 3677 3679 3683 3684 3686 3692 3693 3699 3701 3708 3705 3712 3716 3716
		3719 3725 3723 3729 3732 3732 3740 3744 3747 3748 3753 3756 3757 3763 3763 3764 3771 3772 3772 3777 3780 3784 3789 3792 3797
		3795 3804 3806 3808 3810 3813 3813 3819 3823 3820 3826 3829 3832 3836 3841 3844 3847 3848 3857 3858 3858 3861 3863 3867 3873
		3873 3874 3881 3886 3886 3892 3894 3894 3897 3902 3901 3906 3911 3909 3915 3920 3919 3926 3926 3932 3936 3936 3939 3938 3945
		3947 3947 3951 3955 3955 3962 3964 3965 3971 3975 3979 3981 3983 3985 3988 3991 3992 3994 3996 4002 4001 4008 4013 4016 4020
		4022 4027 4025 4031 4032 4033 4038 4041 4038 4046 4048 4050 4058 4062 4064 4066 4068 4071 4071 4074 4078 4079 4082 4087 4086
		4087 4091 4094
	>;
};
